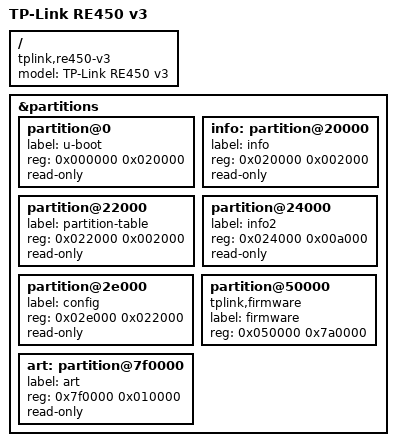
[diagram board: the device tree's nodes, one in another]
// SPDX-License-Identifier: GPL-2.0-or-later OR MIT
/dts-v1/;

#include "qca9563_tplink_re450.dtsi"

/ {
	compatible = "tplink,re450-v3", "qca,qca9563";
	model = "TP-Link RE450 v3";
};

&partitions {
	partition@0 {
		label = "u-boot";
		reg = <0x000000 0x020000>;
		read-only;
	};

	info: partition@20000 {
		label = "info";
		reg = <0x020000 0x002000>;
		read-only;
	};

	partition@22000 {
		label = "partition-table";
		reg = <0x022000 0x002000>;
		read-only;
	};

	partition@24000 {
		label = "info2";
		reg = <0x024000 0x00a000>;
		read-only;
	};

	partition@2e000 {
		label = "config";
		reg = <0x02e000 0x022000>;
		read-only;
	};

	partition@50000 {
		compatible = "tplink,firmware";
		label = "firmware";
		reg = <0x050000 0x7a0000>;
	};

	art: partition@7f0000 {
		label = "art";
		reg = <0x7f0000 0x010000>;
		read-only;
	};
};
